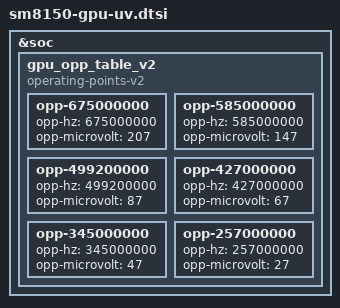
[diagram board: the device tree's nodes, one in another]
&soc {
	gpu_opp_table_v2: gpu_opp_table_v2 {
		compatible = "operating-points-v2";

		opp-675000000 {
			opp-hz = /bits/ 64 <675000000>;
			opp-microvolt = <207>; // MIN
		};

		opp-585000000 {
			opp-hz = /bits/ 64 <585000000>;
			opp-microvolt = <147>; // MIN
		};

		opp-499200000 {
			opp-hz = /bits/ 64 <499200000>;
			opp-microvolt = <87>; // MIN
		};

		opp-427000000 {
			opp-hz = /bits/ 64 <427000000>;
			opp-microvolt = <67>; // MIN
		};

		opp-345000000 {
			opp-hz = /bits/ 64 <345000000>;
			opp-microvolt = <47>; // MIN
		};

		opp-257000000 {
			opp-hz = /bits/ 64 <257000000>;
			opp-microvolt = <27>; // MIN
		};
	};
};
